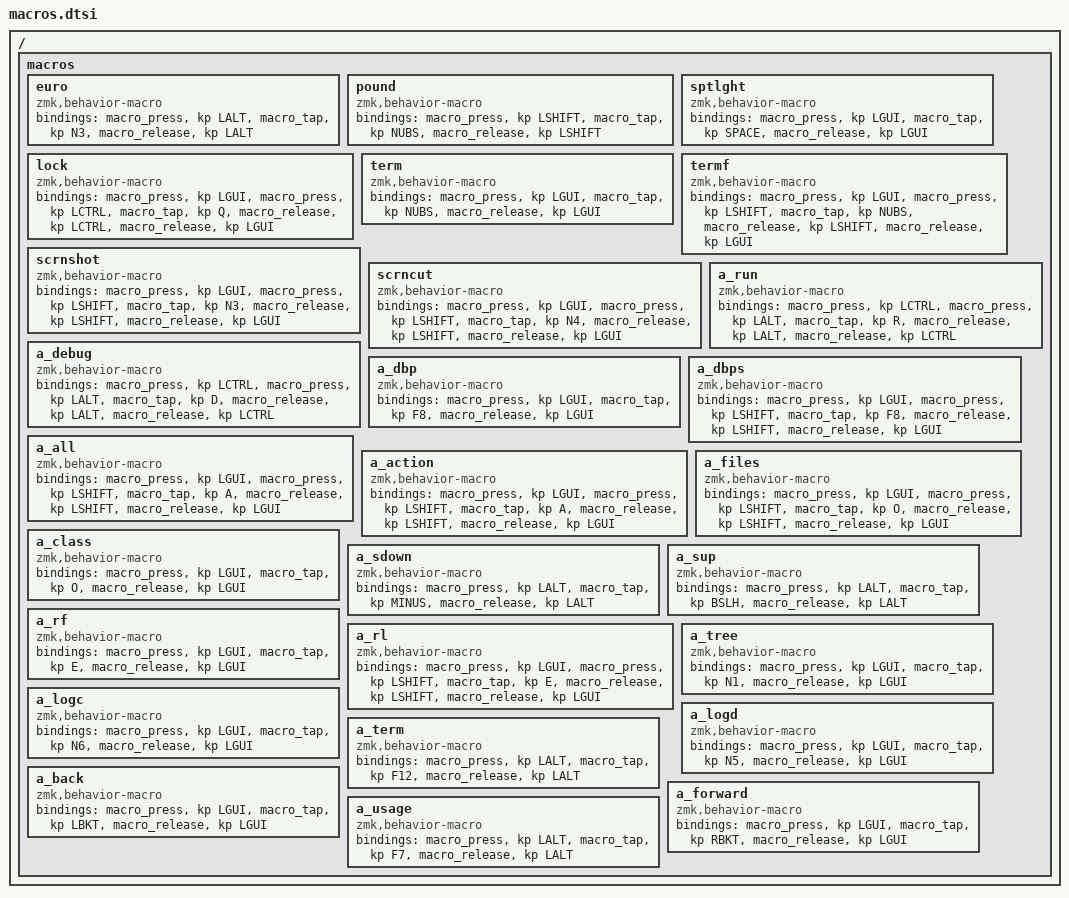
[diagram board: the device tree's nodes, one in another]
/ {
    macros {
        // CURRENCIES
        euro: euro {
            compatible = "zmk,behavior-macro";
            #binding-cells = <0>;
            bindings
                = <&macro_press &kp LALT>
                , <&macro_tap &kp N3>
                , <&macro_release &kp LALT>
                ;
        };
        pound: pound {
            compatible = "zmk,behavior-macro";
            #binding-cells = <0>;
            bindings
                = <&macro_press &kp LSHIFT>
                , <&macro_tap &kp NUBS>
                , <&macro_release &kp LSHIFT>
                ;
        };
        // SYSTEM
        sptlght: sptlght {
            compatible = "zmk,behavior-macro";
            #binding-cells = <0>;
            bindings
                = <&macro_press &kp LGUI>
                , <&macro_tap &kp SPACE>
                , <&macro_release &kp LGUI>
                ;
        };
        lock: lock {
            compatible = "zmk,behavior-macro";
            #binding-cells = <0>;
            bindings
                = <&macro_press &kp LGUI>
                , <&macro_press &kp LCTRL>
                , <&macro_tap &kp Q>
                , <&macro_release &kp LCTRL>
                , <&macro_release &kp LGUI>
                ;
        };
        term: term {
            compatible = "zmk,behavior-macro";
            #binding-cells = <0>;
            bindings
                = <&macro_press &kp LGUI>
                , <&macro_tap &kp NUBS>
                , <&macro_release &kp LGUI>
                ;
        };
        termf: termf {
            compatible = "zmk,behavior-macro";
            #binding-cells = <0>;
            bindings
                = <&macro_press &kp LGUI>
                , <&macro_press &kp LSHIFT>
                , <&macro_tap &kp NUBS>
                , <&macro_release &kp LSHIFT>
                , <&macro_release &kp LGUI>
                ;
        };
        scrnshot: scrnshot {
            compatible = "zmk,behavior-macro";
            #binding-cells = <0>;
            bindings
                = <&macro_press &kp LGUI>
                , <&macro_press &kp LSHIFT>
                , <&macro_tap &kp N3>
                , <&macro_release &kp LSHIFT>
                , <&macro_release &kp LGUI>
                ;
        };
        scrncut: scrncut {
            compatible = "zmk,behavior-macro";
            #binding-cells = <0>;
            bindings
                = <&macro_press &kp LGUI>
                , <&macro_press &kp LSHIFT>
                , <&macro_tap &kp N4>
                , <&macro_release &kp LSHIFT>
                , <&macro_release &kp LGUI>
                ;
        };
        // ANDROID STUDIO
        a_run: a_run {
            compatible = "zmk,behavior-macro";
            #binding-cells = <0>;
            bindings
                = <&macro_press &kp LCTRL>
                , <&macro_press &kp LALT>
                , <&macro_tap &kp R>
                , <&macro_release &kp LALT>
                , <&macro_release &kp LCTRL>
                ;
        };
        a_debug: a_debug {
            compatible = "zmk,behavior-macro";
            #binding-cells = <0>;
            bindings
                = <&macro_press &kp LCTRL>
                , <&macro_press &kp LALT>
                , <&macro_tap &kp D>
                , <&macro_release &kp LALT>
                , <&macro_release &kp LCTRL>
                ;
        };
        a_dbp: a_dbp {
            compatible = "zmk,behavior-macro";
            #binding-cells = <0>;
            bindings
                = <&macro_press &kp LGUI>
                , <&macro_tap &kp F8>
                , <&macro_release &kp LGUI>
                ;
        };
        a_dbps: a_dbps {
            compatible = "zmk,behavior-macro";
            #binding-cells = <0>;
            bindings
                = <&macro_press &kp LGUI>
                , <&macro_press &kp LSHIFT>
                , <&macro_tap &kp F8>
                , <&macro_release &kp LSHIFT>
                , <&macro_release &kp LGUI>
                ;
        };
        a_all: a_all {
            compatible = "zmk,behavior-macro";
            #binding-cells = <0>;
            bindings
                = <&macro_press &kp LGUI>
                , <&macro_press &kp LSHIFT>
                , <&macro_tap &kp A>
                , <&macro_release &kp LSHIFT>
                , <&macro_release &kp LGUI>
                ;
        };
        a_action: a_action {
            compatible = "zmk,behavior-macro";
            #binding-cells = <0>;
            bindings
                = <&macro_press &kp LGUI>
                , <&macro_press &kp LSHIFT>
                , <&macro_tap &kp A>
                , <&macro_release &kp LSHIFT>
                , <&macro_release &kp LGUI>
                ;
        };
        a_files: a_files {
            compatible = "zmk,behavior-macro";
            #binding-cells = <0>;
            bindings
                = <&macro_press &kp LGUI>
                , <&macro_press &kp LSHIFT>
                , <&macro_tap &kp O>
                , <&macro_release &kp LSHIFT>
                , <&macro_release &kp LGUI>
                ;
        };
        a_class: a_class {
            compatible = "zmk,behavior-macro";
            #binding-cells = <0>;
            bindings
                = <&macro_press &kp LGUI>
                , <&macro_tap &kp O>
                , <&macro_release &kp LGUI>
                ;
        };
        a_sdown: a_sdown {
            compatible = "zmk,behavior-macro";
            #binding-cells = <0>;
            bindings
                = <&macro_press &kp LALT>
                , <&macro_tap &kp MINUS>
                , <&macro_release &kp LALT>
                ;
        };
        a_sup: a_sup {
            compatible = "zmk,behavior-macro";
            #binding-cells = <0>;
            bindings
                = <&macro_press &kp LALT>
                , <&macro_tap &kp BSLH>
                , <&macro_release &kp LALT>
                ;
        };
        a_rf: a_rf {
            compatible = "zmk,behavior-macro";
            #binding-cells = <0>;
            bindings
                = <&macro_press &kp LGUI>
                , <&macro_tap &kp E>
                , <&macro_release &kp LGUI>
                ;
        };
        a_rl: a_rl {
            compatible = "zmk,behavior-macro";
            #binding-cells = <0>;
            bindings
                = <&macro_press &kp LGUI>
                , <&macro_press &kp LSHIFT>
                , <&macro_tap &kp E>
                , <&macro_release &kp LSHIFT>
                , <&macro_release &kp LGUI>
                ;
        };
        a_tree: a_tree {
            compatible = "zmk,behavior-macro";
            #binding-cells = <0>;
            bindings
                = <&macro_press &kp LGUI>
                , <&macro_tap &kp N1>
                , <&macro_release &kp LGUI>
                ;
        };
        a_logc: a_logc {
            compatible = "zmk,behavior-macro";
            #binding-cells = <0>;
            bindings
                = <&macro_press &kp LGUI>
                , <&macro_tap &kp N6>
                , <&macro_release &kp LGUI>
                ;
        };
        a_logd: a_logd {
            compatible = "zmk,behavior-macro";
            #binding-cells = <0>;
            bindings
                = <&macro_press &kp LGUI>
                , <&macro_tap &kp N5>
                , <&macro_release &kp LGUI>
                ;
        };
        a_term: a_term {
            compatible = "zmk,behavior-macro";
            #binding-cells = <0>;
            bindings
                = <&macro_press &kp LALT>
                , <&macro_tap &kp F12>
                , <&macro_release &kp LALT>
                ;
        };
        a_back: a_back {
            compatible = "zmk,behavior-macro";
            #binding-cells = <0>;
            bindings
                = <&macro_press &kp LGUI>
                , <&macro_tap &kp LBKT>
                , <&macro_release &kp LGUI>
                ;
                
        };
        a_forward: a_forward {
            compatible = "zmk,behavior-macro";
            #binding-cells = <0>;
            bindings
                = <&macro_press &kp LGUI>
                , <&macro_tap &kp RBKT>
                , <&macro_release &kp LGUI>
                ;
        };
        a_usage: a_usage {
            compatible = "zmk,behavior-macro";
            #binding-cells = <0>;
            bindings
                = <&macro_press &kp LALT>
                , <&macro_tap &kp F7>
                , <&macro_release &kp LALT>
                ;
        };
    };
};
